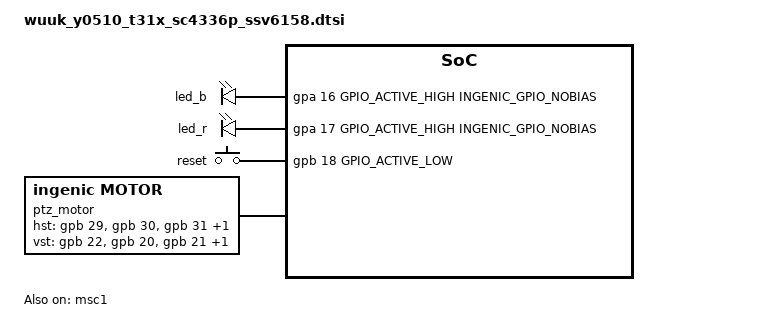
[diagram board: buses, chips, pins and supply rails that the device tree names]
// WUUK Y0510 (T31X, SC4336P, SSV6158) per-board GPIO definitions.
// Injected into the kernel 4.4+ device tree; ignored on 3.10.

#include <dt-bindings/gpio/gpio.h>
#include <dt-bindings/input/input.h>
#include <dt-bindings/pinctrl/ingenic-pinctrl.h>

/ {
	gpio-leds {
		compatible = "gpio-leds";

		led_b {
			label = "led_b";
			gpios = <&gpa 16 GPIO_ACTIVE_HIGH INGENIC_GPIO_NOBIAS>;
			default-state = "off";
		};

		led_r {
			label = "led_r";
			gpios = <&gpa 17 GPIO_ACTIVE_HIGH INGENIC_GPIO_NOBIAS>;
			default-state = "off";
		};
	};
};

/* Card detect; the family tree carries the reference pin. */
&msc0 {
	ingenic,cd-gpios = <&gpb 17 GPIO_ACTIVE_LOW INGENIC_GPIO_PULLUP>;
};

/* SDIO WLAN (ssv6158) hangs off MMC1 on PB8-11/PB13-14; the family tree
   disables msc1 because it uses MSC0 for the card slot. The WLAN power pin
   (gpio.wlan = 8) is raised from userspace, so poll for the card instead of
   scanning once at boot (broken-cd), as on the Cinnado D1. */
&msc1 {
	status = "okay";
	pinctrl-names = "default";
	pinctrl-0 = <&msc1_pb>;
	ingenic,sdio_clk = <1>;
	max-frequency = <24000000>;
	broken-cd;
};

/* This board is WiFi-only, but the generic T31 tree enables the MAC, whose
   RMII pinmux claims PB6-14 - the same pins MSC1/SDIO needs. Disable it. */
&mac {
	status = "disabled";
};

/* The reference tree enables I2C1 on PB25/PB26 (i2c1_pb); this board wires
   those pins to the IR-CUT (gpio.ircut = "57 58"), so i2c1 must not hold the
   pinmux. */
&i2c1 {
	status = "disabled";
};

/ {
	gpio-keys {
		compatible = "gpio-keys";
		label = "gpio-keys";

		reset {
			label = "reset";
			linux,code = <KEY_ENTER>;
			gpios = <&gpb 18 GPIO_ACTIVE_LOW INGENIC_GPIO_PULLUP>;
		};
	};
};

/* Speaker amplifier enable: PA7, active high (aperto BR2_THINGINO_AUDIO_GPIO=7,
   /etc/modules.d/40-audio "spk_gpio=7 spk_level=1"). The t31 codec drives it
   only while a playback stream runs. */
&codec {
	speaker-enable-gpios = <&gpa 7 GPIO_ACTIVE_HIGH>;
};

/* PTZ stepper motors: pan PB29/PB30/PB31/PB19, tilt PB22/PB20/PB21/PC0.
   The pins and step counts come from thingino.json gpio_pan/gpio_tilt
   ("61 62 63 51", "54 52 53 64") and steps_pan/steps_tilt. */
/ {
	ptz_motor: motor {
		compatible = "ingenic,motor";

		hst-gpios = <&gpb 29 GPIO_ACTIVE_HIGH>,
			    <&gpb 30 GPIO_ACTIVE_HIGH>,
			    <&gpb 31 GPIO_ACTIVE_HIGH>,
			    <&gpb 19 GPIO_ACTIVE_HIGH>;
		vst-gpios = <&gpb 22 GPIO_ACTIVE_HIGH>,
			    <&gpb 20 GPIO_ACTIVE_HIGH>,
			    <&gpb 21 GPIO_ACTIVE_HIGH>,
			    <&gpc 0 GPIO_ACTIVE_HIGH>;

		ingenic,hmaxstep = <4050>;
		ingenic,vmaxstep = <1000>;
	};
};
